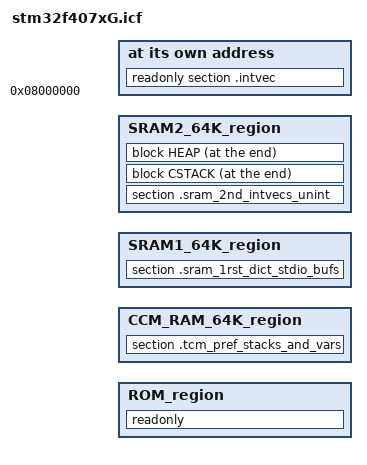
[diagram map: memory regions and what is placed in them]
/*###ICF### Section handled by ICF editor, don't touch! ****/
/*-Editor annotation file-*/
/* IcfEditorFile="$TOOLKIT_DIR$\config\ide\IcfEditor\cortex_v1_0.xml" */
/*-Specials-*/
define symbol __ICFEDIT_intvec_start__ = 0x08000000;
/*-Memory Regions-*/
define symbol __ICFEDIT_region_ROM_start__ = 0x08000000;
define symbol __ICFEDIT_region_ROM_end__   = 0x080FFFFF;
define symbol __ICFEDIT_region_RAM_start__ = 0x10000000;
define symbol __ICFEDIT_region_RAM_end__   = 0x1000FFFF;
/*-Sizes-*/
define symbol __ICFEDIT_size_cstack__ = 0x2000;
define symbol __ICFEDIT_size_heap__   = 0x2000;
/**** End of ICF editor section. ###ICF###*/

define symbol __region_SRAM1_start__ = 0x20000000;
define symbol __region_SRAM1_end__   = 0x2000FFFF;
define symbol __region_SRAM2_start__ = 0x20010000;
define symbol __region_SRAM2_end__   = 0x2001FFFF;

define memory mem with size = 4G;
define region ROM_region = mem:[from ICFEDIT_region_ROM_start to_ICFEDIT_region_ROM_end__];
define region CCM_RAM_64K_region = mem:[from ICFEDIT_region_RAM_start_to_ICFEDIT_region_RAM_end__];
define region SRAM1_64K_region = mem:[from_region_SRAM1_start to region_SRAM1_end__];
define region SRAM2_64K_region = mem:[from region_SRAM2_start to_region_SRAM2_end__];

define block CSTACK    with alignment = 8, size = __ICFEDIT_size_cstack__   { };
define block HEAP      with alignment = 8, size = __ICFEDIT_size_heap__     { };

//initialize by copy { section .noinint }; // , readwrite

do not initialize { zeroinit };
do not initialize { section .noinit };

do not initialize  { section .sram_1rst_dict_stdio_bufs }; // error Lp049
// Fatal Error[Lp049]: there was no reference to_iar_data_init3,
// but it is needed to initialize section .sram_1rst_dict_stdio_bufs
// in (FISH_STM32F4_IAR.o #6

do not initialize  { section .sram_2nd_intvecs_unint };
do not initialize  { readwrite, section .tcm_pref_stacks_and_vars  };

section .sram_1rst_dict_stdio_bufs
place at address mem:__ICFEDIT_intvec_start__ { readonly section .intvec };

place in ROM_region   { readonly };
place in CCM_RAM_64K_region   { section .tcm_pref_stacks_and_vars };
place in SRAM1_64K_region  { section .sram_1rst_dict_stdio_bufs };
place in SRAM2_64K_region  { section .sram_2nd_intvecs_unint };
place at end of SRAM2_64K_region  { block CSTACK, block HEAP };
